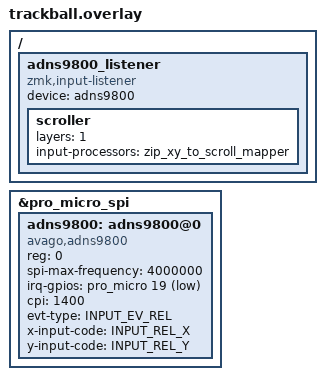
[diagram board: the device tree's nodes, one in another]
#include <dt-bindings/input/input-event-codes.h>
#include <input/processors.dtsi>
#include "trackball.dtsi"

&pro_micro_spi {
    adns9800: adns9800@0 {
        status = "okay";
        compatible = "avago,adns9800";
        reg = <0>;
        spi-max-frequency = <4000000>;
        irq-gpios = <&pro_micro 19 (GPIO_ACTIVE_LOW | GPIO_PULL_UP)>;
        cpi = <1400>;
        evt-type = <INPUT_EV_REL>;
        x-input-code = <INPUT_REL_X>;
        y-input-code = <INPUT_REL_Y>;
    };
};

/ {
    adns9800_listener: adns9800_listener {
        compatible = "zmk,input-listener";
        device = <&adns9800>;
        scroller {
            layers = <1>;
            input-processors = <&zip_xy_to_scroll_mapper>;
        };
    };
};
